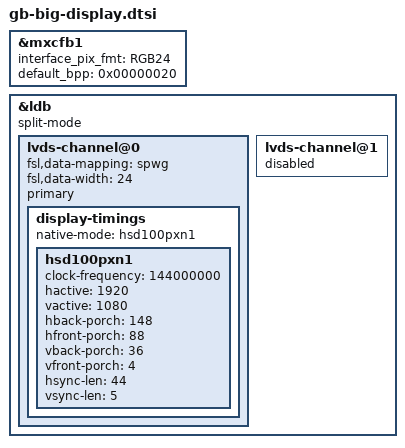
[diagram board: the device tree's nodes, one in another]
/*
 * Copyright (C) 2015-2017 Variscite Ltd.
 *
 * This program is free software; you can redistribute it and/or modify
 * it under the terms of the GNU General Public License version 2 as
 * published by the Free Software Foundation.
 *
 * Resistive Display for VAR-MX6CustomBoard
 */

&mxcfb1 {
	interface_pix_fmt = "RGB24";
    default_bpp = <0x00000020>;
};

&ldb {
	status = "okay";
    split-mode;
	lvds-channel@0 {
		fsl,data-mapping = "spwg";
		fsl,data-width = <24>;
		status = "okay";
		primary;
		display-timings {
			native-mode = <&hsd100pxn1>;
			hsd100pxn1: hsd100pxn1 {
				clock-frequency = <144000000>;
				hactive = <1920>;
				vactive = <1080>;
				hback-porch = <148>;
				hfront-porch = <88>;
				vback-porch = <36>;
				vfront-porch = <4>;
				hsync-len = <44>;
				vsync-len = <5>;
			};
		};
	};

	lvds-channel@1 {
                status = "disabled";
	};
};
